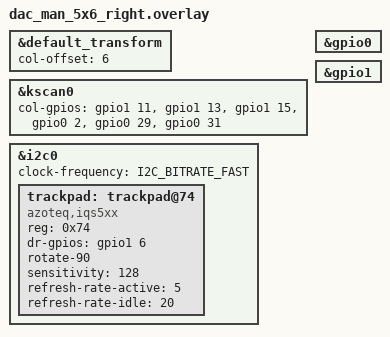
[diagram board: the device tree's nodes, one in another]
#include "dac_man_5x6.dtsi"

&default_transform {
    col-offset = <6>;
};

&kscan0 {
    col-gpios
        = <&gpio1 11 GPIO_ACTIVE_HIGH>
        , <&gpio1 13 GPIO_ACTIVE_HIGH>
        , <&gpio1 15 GPIO_ACTIVE_HIGH>
        , <&gpio0 2  GPIO_ACTIVE_HIGH>
        , <&gpio0 29 GPIO_ACTIVE_HIGH>
        , <&gpio0 31 GPIO_ACTIVE_HIGH>
        ;
};

// Enable GPIO controllers
&gpio0 {
    status = "okay";
};

&gpio1 {
    status = "okay";
};

&i2c0 {
    status = "okay";
    clock-frequency = <I2C_BITRATE_FAST>;

    trackpad: trackpad@74 {
        compatible = "azoteq,iqs5xx";
        reg = <0x74>;
        dr-gpios = <&gpio1 6 GPIO_ACTIVE_HIGH>;
        status = "okay";
        rotate-90;
        sensitivity = <128>;
        refresh-rate-active = <5>;
        refresh-rate-idle = <20>;
    };
};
